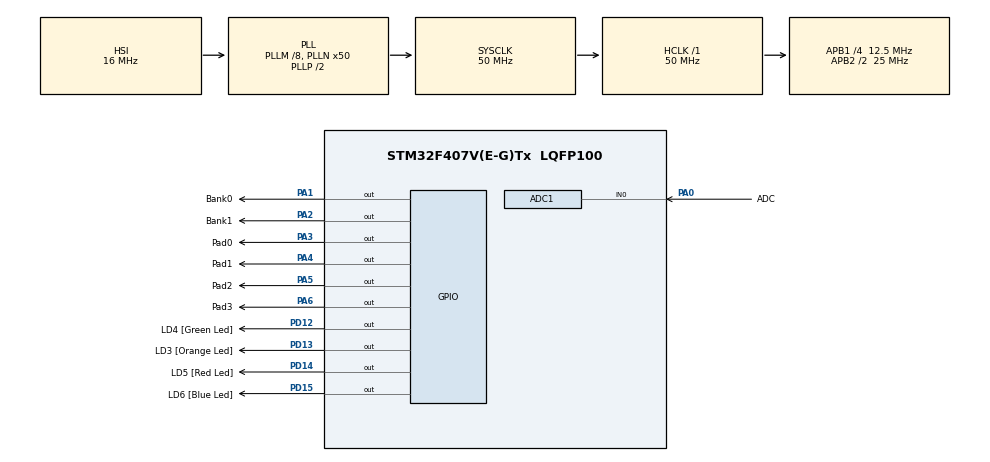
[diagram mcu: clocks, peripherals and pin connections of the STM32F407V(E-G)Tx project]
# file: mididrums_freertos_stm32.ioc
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ADC1.Channel-0\#ChannelRegularConversion=ADC_CHANNEL_0
ADC1.NbrOfConversionFlag=1
ADC1.Rank-0\#ChannelRegularConversion=1
ADC1.SamplingTime-0\#ChannelRegularConversion=ADC_SAMPLETIME_3CYCLES
ADC1.master=1
FREERTOS.Tasks01=defaultTask,24,128,StartDefaultTask,Default,NULL,Dynamic,NULL,NULL
FREERTOS.configCHECK_FOR_STACK_OVERFLOW=1
FREERTOS.configRECORD_STACK_HIGH_ADDRESS=1
FREERTOS.configUSE_MALLOC_FAILED_HOOK=1
Mcu.Family=STM32F4
Mcu.Name=STM32F407V(E-G)Tx
Mcu.Package=LQFP100
NVIC.PriorityGroup=NVIC_PRIORITYGROUP_4
NVIC.TIM1_UP_TIM10_IRQn=true\:0\:0\:false\:false\:true\:false\:false\:true
NVIC.TimeBase=TIM1_UP_TIM10_IRQn
NVIC.TimeBaseIP=TIM1
PA0-WKUP.GPIO_Label=ADC
PA0-WKUP.Signal=ADCx_IN0
PA1.GPIO_Label=Bank0
PA1.GPIO_PuPd=GPIO_NOPULL
PA1.Signal=GPIO_Output
PA2.GPIO_Label=Bank1
PA2.GPIO_PuPd=GPIO_NOPULL
PA2.Signal=GPIO_Output
PA3.GPIO_Label=Pad0
PA3.GPIO_PuPd=GPIO_NOPULL
PA3.Signal=GPIO_Output
PA4.GPIO_Label=Pad1
PA4.GPIO_PuPd=GPIO_NOPULL
PA4.Signal=GPIO_Output
PA5.GPIO_Label=Pad2
PA5.GPIO_PuPd=GPIO_NOPULL
PA5.Signal=GPIO_Output
PA6.GPIO_Label=Pad3
PA6.GPIO_PuPd=GPIO_NOPULL
PA6.Signal=GPIO_Output
PD12.GPIO_Label=LD4 [Green Led]
PD12.GPIO_PuPd=GPIO_NOPULL
PD12.GPIO_Speed=GPIO_SPEED_FREQ_LOW
PD12.Signal=GPIO_Output
PD13.GPIO_Label=LD3 [Orange Led]
PD13.GPIO_PuPd=GPIO_NOPULL
PD13.GPIO_Speed=GPIO_SPEED_FREQ_LOW
PD13.Signal=GPIO_Output
PD14.GPIO_Label=LD5 [Red Led]
PD14.GPIO_PuPd=GPIO_NOPULL
PD14.GPIO_Speed=GPIO_SPEED_FREQ_LOW
PD14.Signal=GPIO_Output
PD15.GPIO_Label=LD6 [Blue Led]
PD15.GPIO_PuPd=GPIO_NOPULL
PD15.GPIO_Speed=GPIO_SPEED_FREQ_LOW
PD15.Signal=GPIO_Output
ProjectManager.HeapSize=0x200
ProjectManager.StackSize=0x400
ProjectManager.TargetToolchain=STM32CubeIDE
RCC.48MHZClocksFreq_Value=14285714.285714285
RCC.AHBFreq_Value=50000000
RCC.APB1CLKDivider=RCC_HCLK_DIV4
RCC.APB1Freq_Value=12500000
RCC.APB1TimFreq_Value=25000000
RCC.APB2CLKDivider=RCC_HCLK_DIV2
RCC.APB2Freq_Value=25000000
RCC.APB2TimFreq_Value=50000000
RCC.CortexFreq_Value=50000000
RCC.HCLKFreq_Value=50000000
RCC.HSE_VALUE=8000000
RCC.HSI_VALUE=16000000
RCC.PLLM=8
RCC.PLLN=50
RCC.PLLQ=7
RCC.SYSCLKFreq_VALUE=50000000
RCC.SYSCLKSource=RCC_SYSCLKSOURCE_PLLCLK
RCC.VCOOutputFreq_Value=100000000
SH.ADCx_IN0.0=ADC1_IN0,IN0
VP_FREERTOS_VS_CMSIS_V2.Mode=CMSIS_V2
VP_SYS_VS_tim1.Mode=TIM1
board=STM32F407G-DISC1

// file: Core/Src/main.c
/* USER CODE BEGIN Header */
/**
  ******************************************************************************
  * @file           : main.c
  * @brief          : Main program body
  ******************************************************************************
  * @attention
  *
  * <h2><center>&copy; Copyright (c) 2020 STMicroelectronics.
  * All rights reserved.</center></h2>
  *
  * This software component is licensed by ST under Ultimate Liberty license
  * SLA0044, the "License"; You may not use this file except in compliance with
  * the License. You may obtain a copy of the License at:
  *                             www.st.com/SLA0044
  *
  ******************************************************************************
  */
/* USER CODE END Header */

#include <tasks/mainTask.h>
#include "main.h"
#include "cmsis_os.h"

ADC_HandleTypeDef hadc1;

/* Definitions for defaultTask */
//osThreadId_t defaultTaskHandle;
//const osThreadAttr_t defaultTask_attributes = {
//  .name = "defaultTask",
//  .priority = (osPriority_t) osPriorityNormal,
//  .stack_size = 128 * 4
//};
/* USER CODE BEGIN PV */

osThreadId_t mainTaskHandle;
const osThreadAttr_t mainTask_attributes = {
		.name = "mainTask",
		.priority = (osPriority_t) osPriorityNormal,
		.stack_size = 32*4
};

/* USER CODE END PV */

void SystemClock_Config(void);
static void MX_GPIO_Init(void);
static void MX_ADC1_Init(void);

int main(void)
{

  /* MCU Configuration--------------------------------------------------------*/

  /* Reset of all peripherals, Initializes the Flash interface and the Systick. */
  HAL_Init();

  /* Configure the system clock */
  SystemClock_Config();

  /* Initialize all configured peripherals */
  MX_GPIO_Init();
  MX_ADC1_Init();

  /* Init scheduler */
  osKernelInitialize();

  /* Create the thread(s) */
  /* creation of defaultTask */
  //defaultTaskHandle = osThreadNew(StartDefaultTask, NULL, &defaultTask_attributes);
  mainTaskHandle = osThreadNew(mainTask, &hadc1, &mainTask_attributes);

  /* Start scheduler */
  osKernelStart();

  /* We should never get here as control is now taken by the scheduler */
  /* Infinite loop */
  while (1)
  {

  }
}

void SystemClock_Config(void)
{
  RCC_OscInitTypeDef RCC_OscInitStruct = {0};
  RCC_ClkInitTypeDef RCC_ClkInitStruct = {0};

  /** Configure the main internal regulator output voltage
  */
  __HAL_RCC_PWR_CLK_ENABLE();
  __HAL_PWR_VOLTAGESCALING_CONFIG(PWR_REGULATOR_VOLTAGE_SCALE1);
  /** Initializes the CPU, AHB and APB busses clocks
  */
  RCC_OscInitStruct.OscillatorType = RCC_OSCILLATORTYPE_HSI;
  RCC_OscInitStruct.HSIState = RCC_HSI_ON;
  RCC_OscInitStruct.HSICalibrationValue = RCC_HSICALIBRATION_DEFAULT;
  RCC_OscInitStruct.PLL.PLLState = RCC_PLL_ON;
  RCC_OscInitStruct.PLL.PLLSource = RCC_PLLSOURCE_HSI;
  RCC_OscInitStruct.PLL.PLLM = 8;
  RCC_OscInitStruct.PLL.PLLN = 50;
  RCC_OscInitStruct.PLL.PLLP = RCC_PLLP_DIV2;
  RCC_OscInitStruct.PLL.PLLQ = 7;
  if (HAL_RCC_OscConfig(&RCC_OscInitStruct) != HAL_OK)
  {
    Error_Handler();
  }
  /** Initializes the CPU, AHB and APB busses clocks
  */
  RCC_ClkInitStruct.ClockType = RCC_CLOCKTYPE_HCLK|RCC_CLOCKTYPE_SYSCLK
                              |RCC_CLOCKTYPE_PCLK1|RCC_CLOCKTYPE_PCLK2;
  RCC_ClkInitStruct.SYSCLKSource = RCC_SYSCLKSOURCE_PLLCLK;
  RCC_ClkInitStruct.AHBCLKDivider = RCC_SYSCLK_DIV1;
  RCC_ClkInitStruct.APB1CLKDivider = RCC_HCLK_DIV4;
  RCC_ClkInitStruct.APB2CLKDivider = RCC_HCLK_DIV2;

  if (HAL_RCC_ClockConfig(&RCC_ClkInitStruct, FLASH_LATENCY_1) != HAL_OK)
  {
    Error_Handler();
  }
}

static void MX_ADC1_Init(void)
{

  ADC_ChannelConfTypeDef sConfig = {0};

  /** Configure the global features of the ADC (Clock, Resolution, Data Alignment and number of conversion)
  */
  hadc1.Instance = ADC1;
  hadc1.Init.ClockPrescaler = ADC_CLOCK_SYNC_PCLK_DIV2;
  hadc1.Init.Resolution = ADC_RESOLUTION_12B;
  hadc1.Init.ScanConvMode = DISABLE;
  hadc1.Init.ContinuousConvMode = ENABLE;
  hadc1.Init.DiscontinuousConvMode = DISABLE;
  hadc1.Init.ExternalTrigConvEdge = ADC_EXTERNALTRIGCONVEDGE_NONE;
  hadc1.Init.ExternalTrigConv = ADC_SOFTWARE_START;
  hadc1.Init.DataAlign = ADC_DATAALIGN_RIGHT;
  hadc1.Init.NbrOfConversion = 1;
  hadc1.Init.DMAContinuousRequests = DISABLE;
  hadc1.Init.EOCSelection = ADC_EOC_SEQ_CONV;
  if (HAL_ADC_Init(&hadc1) != HAL_OK)
  {
    Error_Handler();
  }
  /** Configure for the selected ADC regular channel its corresponding rank in the sequencer and its sample time.
  */
  sConfig.Channel = ADC_CHANNEL_0;
  sConfig.Rank = 1;
  sConfig.SamplingTime = ADC_SAMPLETIME_3CYCLES;
  if (HAL_ADC_ConfigChannel(&hadc1, &sConfig) != HAL_OK)
  {
    Error_Handler();
  }

}

static void MX_GPIO_Init(void)
{
  GPIO_InitTypeDef GPIO_InitStruct = {0};

  /* GPIO Ports Clock Enable */
  __HAL_RCC_GPIOA_CLK_ENABLE();
  __HAL_RCC_GPIOD_CLK_ENABLE();

  /*Configure GPIO pin Output Level */
  HAL_GPIO_WritePin(GPIOA, Bank0_Pin|Bank1_Pin|Pad0_Pin|Pad1_Pin
                          |Pad2_Pin|Pad3_Pin, GPIO_PIN_RESET);

  /*Configure GPIO pin Output Level */
  HAL_GPIO_WritePin(GPIOD, LD4_Pin|LD3_Pin|LD5_Pin|LD6_Pin, GPIO_PIN_RESET);

  /*Configure GPIO pins : Bank0_Pin Bank1_Pin Pad0_Pin Pad1_Pin
                           Pad2_Pin Pad3_Pin */
  GPIO_InitStruct.Pin = Bank0_Pin|Bank1_Pin|Pad0_Pin|Pad1_Pin
                          |Pad2_Pin|Pad3_Pin;
  GPIO_InitStruct.Mode = GPIO_MODE_OUTPUT_PP;
  GPIO_InitStruct.Pull = GPIO_NOPULL;
  GPIO_InitStruct.Speed = GPIO_SPEED_FREQ_LOW;
  HAL_GPIO_Init(GPIOA, &GPIO_InitStruct);

  /*Configure GPIO pins : LD4_Pin LD3_Pin LD5_Pin LD6_Pin */
  GPIO_InitStruct.Pin = LD4_Pin|LD3_Pin|LD5_Pin|LD6_Pin;
  GPIO_InitStruct.Mode = GPIO_MODE_OUTPUT_PP;
  GPIO_InitStruct.Pull = GPIO_NOPULL;
  GPIO_InitStruct.Speed = GPIO_SPEED_FREQ_LOW;
  HAL_GPIO_Init(GPIOD, &GPIO_InitStruct);

}

//void StartDefaultTask(void *argument)
//{
//  /* USER CODE BEGIN 5 */
//
//	// ADC
//	if (HAL_ADC_Start(&hadc1) != HAL_OK)
//	{
//		for(;;)
//		{
//			// ADC failed to start
//		}
//	}
//
//  /* Infinite loop */
//	uint32_t timeout = 100;
//	uint32_t adcvalue = 0;
//	uint32_t min_adcvalue = UINT32_MAX;
//  for(;;)
//  {
//	  if (HAL_ADC_PollForConversion(&hadc1, timeout) == HAL_OK)
//	  {
//		  adcvalue = HAL_ADC_GetValue(&hadc1);
//		  if (adcvalue < min_adcvalue)
//		  {
//			  min_adcvalue = adcvalue;
//		  }
//	  }
//  }
//  /* USER CODE END 5 */
//}

 /**
  * @brief  Period elapsed callback in non blocking mode
  * @note   This function is called  when TIM1 interrupt took place, inside
  * HAL_TIM_IRQHandler(). It makes a direct call to HAL_IncTick() to increment
  * a global variable "uwTick" used as application time base.
  * @param  htim : TIM handle
  * @retval None
  */
void HAL_TIM_PeriodElapsedCallback(TIM_HandleTypeDef *htim)
{
  if (htim->Instance == TIM1) {
    HAL_IncTick();
  }
}

void Error_Handler(void)
{
}

/************************ (C) COPYRIGHT STMicroelectronics *****END OF FILE****/
